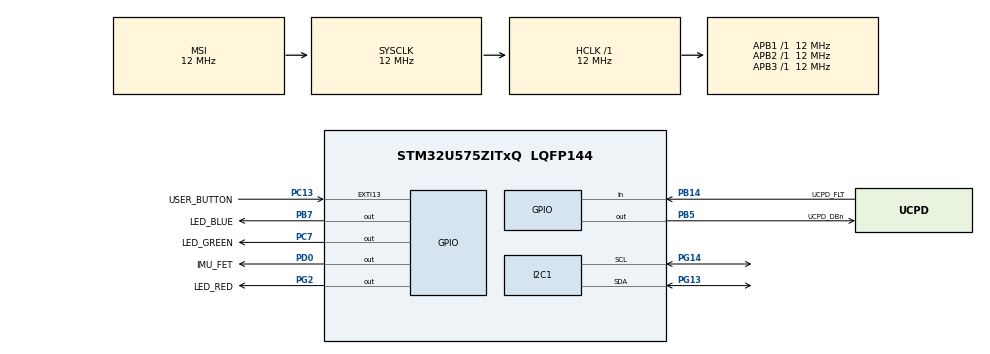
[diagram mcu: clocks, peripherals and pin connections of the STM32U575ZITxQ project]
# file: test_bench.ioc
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CORTEX_M33_NS.userName=CORTEX_M33
I2C1.Timing=0x40000A0B
Mcu.Family=STM32U5
Mcu.Name=STM32U575ZITxQ
Mcu.Package=LQFP144
NVIC.I2C1_ER_IRQn=true\:0\:0\:false\:false\:true\:true\:true\:true
NVIC.I2C1_EV_IRQn=true\:0\:0\:false\:false\:true\:true\:true\:true
NVIC.PriorityGroup=NVIC_PRIORITYGROUP_3
PA10.GPIO_Label=USART1_RX
PA10.GPIO_PuPd=GPIO_PULLDOWN
PA10.GPIO_Speed=GPIO_SPEED_FREQ_VERY_HIGH
PA10.Signal=USART1_RX
PA11.GPIO_Label=USB_OTG_FS_DM
PA11.GPIO_Speed=GPIO_SPEED_FREQ_VERY_HIGH
PA11.Signal=USB_OTG_FS_DM
PA12.GPIO_Label=USB_OTG_FS_DP
PA12.GPIO_Speed=GPIO_SPEED_FREQ_VERY_HIGH
PA12.Signal=USB_OTG_FS_DP
PA13\ (JTMS/SWDIO).Mode=Trace_Asynchronous_SW
PA13\ (JTMS/SWDIO).Signal=DEBUG_JTMS-SWDIO
PA14\ (JTCK/SWCLK).Mode=Trace_Asynchronous_SW
PA14\ (JTCK/SWCLK).Signal=DEBUG_JTCK-SWCLK
PA15\ (JTDI).GPIO_Label=UCPD1_CC1
PA15\ (JTDI).Signal=UCPD1_CC1
PA9.GPIO_Label=USART1_TX
PA9.GPIO_PuPd=GPIO_PULLDOWN
PA9.GPIO_Speed=GPIO_SPEED_FREQ_VERY_HIGH
PA9.Signal=USART1_TX
PB14.GPIO_Label=UCPD_FLT
PB14.Signal=GPIO_Input
PB15.GPIO_Label=UCPD1_CC2
PB15.Signal=UCPD1_CC2
PB3\ (JTDO/TRACESWO).Mode=Trace_Asynchronous_SW
PB3\ (JTDO/TRACESWO).Signal=DEBUG_JTDO-SWO
PB5.GPIO_Label=UCPD_DBn
PB5.Signal=GPIO_Output
PB7.GPIO_Label=LED_BLUE
PB7.GPIO_ModeDefaultOutputPP=GPIO_MODE_OUTPUT_PP
PB7.GPIO_PuPd=GPIO_PULLUP
PB7.GPIO_Speed=GPIO_SPEED_FREQ_HIGH
PB7.Signal=GPIO_Output
PC13.GPIO_Label=USER_BUTTON
PC13.GPIO_ModeDefaultEXTI=GPIO_MODE_IT_FALLING
PC13.Signal=GPXTI13
PC14-OSC32_IN\ (PC14).Mode=LSE-External-Oscillator
PC14-OSC32_IN\ (PC14).Signal=RCC_OSC32_IN
PC15-OSC32_OUT\ (PC15).Mode=LSE-External-Oscillator
PC15-OSC32_OUT\ (PC15).Signal=RCC_OSC32_OUT
PC2.GPIO_Label=VBUS_SENSE
PC2.Signal=ADC1_IN3
PC7.GPIO_Label=LED_GREEN
PC7.GPIO_PuPd=GPIO_PULLUP
PC7.GPIO_Speed=GPIO_SPEED_FREQ_HIGH
PC7.Signal=GPIO_Output
PD0.GPIO_Label=IMU_FET
PD0.PinState=GPIO_PIN_SET
PD0.Signal=GPIO_Output
PG13.GPIO_Pu=GPIO_PULLUP
PG13.GPIO_Speed=GPIO_SPEED_FREQ_VERY_HIGH
PG13.Mode=I2C
PG13.Signal=I2C1_SDA
PG14.GPIO_Pu=GPIO_PULLUP
PG14.GPIO_Speed=GPIO_SPEED_FREQ_VERY_HIGH
PG14.Mode=I2C
PG14.Signal=I2C1_SCL
PG2.GPIO_Label=LED_RED
PG2.GPIO_ModeDefaultOutputPP=GPIO_MODE_OUTPUT_PP
PG2.GPIO_PuPd=GPIO_PULLUP
PG2.GPIO_Speed=GPIO_SPEED_FREQ_HIGH
PG2.Signal=GPIO_Output
PWR.PowerMode=PWR_SMPS_SUPPLY
ProjectManager.HeapSize=0x200
ProjectManager.StackSize=0x400
ProjectManager.TargetToolchain=STM32CubeIDE
RCC.ADCCLockSelection=RCC_ADCDACCLKSOURCE_SYSCLK
RCC.ADCFreq_Value=12000000
RCC.AHBFreq_Value=12000000
RCC.APB1Freq_Value=12000000
RCC.APB1TimFreq_Value=12000000
RCC.APB2Freq_Value=12000000
RCC.APB2TimFreq_Value=12000000
RCC.APB3Freq_Value=12000000
RCC.CortexFreq_Value=12000000
RCC.DACCLockSelectionVirtual=RCC_DAC1CLKSOURCE_LSI
RCC.EPOD_VALUE=12000000
RCC.HCLKFreq_Value=12000000
RCC.HSE_VALUE=16000000
RCC.HSI48_VALUE=48000000
RCC.HSI_VALUE=16000000
RCC.I2C2CLockSelection=RCC_I2C2CLKSOURCE_SYSCLK
RCC.LSIDIV_VALUE=32000
RCC.MSIClockRange=RCC_MSIRANGE_3
RCC.MSI_VALUE=12000000
RCC.PLLN=80
RCC.SYSCLKFreq_VALUE=12000000
RCC.USBFreq_Value=48000000
RCC.VCOOutputFreq_Value=960000000
VP_ICACHE_VS_ICACHE.Mode=DirectMappedCache
VP_LPBAMQUEUE_VS_QUEUE.Mode=QUEUEMODE
VP_LPBAM_VS_SIG1.Mode=SmartRun
VP_LPBAM_VS_SIG4.Mode=LPDMA1
VP_MEMORYMAP_VS_MEMORYMAP.Mode=CurAppReg
VP_PWR_VS_DBSignals.Mode=DisableDeadBatterySignals
VP_PWR_VS_LPOM.Mode=PowerOptimisation
VP_PWR_VS_SECSignals.Mode=Security/Privilege
board=NUCLEO-U575ZI-Q

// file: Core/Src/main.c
/* USER CODE BEGIN Header */
/**
  ******************************************************************************
  * @file           : main.c
  * @brief          : Main program body
  ******************************************************************************
  * @attention
  *
  * Copyright (c) 2022 STMicroelectronics.
  * All rights reserved.
  *
  * This software is licensed under terms that can be found in the LICENSE file
  * in the root directory of this software component.
  * If no LICENSE file comes with this software, it is provided AS-IS.
  *
  ******************************************************************************
  */
/* USER CODE END Header */
#include "main.h"

/* USER CODE BEGIN Includes */
#include <string.h>
#include "stdbool.h"
#include "temp_sensor.h"

/* USER CODE END Includes */

I2C_HandleTypeDef hi2c1;

void SystemClock_Config(void);
static void SystemPower_Config(void);
static void MX_GPIO_Init(void);
static void MX_ICACHE_Init(void);
static void MX_I2C1_Init(void);

/* USER CODE BEGIN 0 */
Temperature temp;
/* USER CODE END 0 */

int main(void)
{

  /* MCU Configuration--------------------------------------------------------*/

  /* Reset of all peripherals, Initializes the Flash interface and the Systick. */
  HAL_Init();

  /* Configure the system clock */
  SystemClock_Config();

  /* Configure the System Power */
  SystemPower_Config();

  /* Initialize all configured peripherals */
  MX_GPIO_Init();
  MX_ICACHE_Init();
  MX_I2C1_Init();

  /* Infinite loop */
  /* USER CODE BEGIN WHILE */

  while (1)
  {
	  float room_temp = 0.0;
	  uint8_t command = 0x11;
	  temperature_init(&temp, &hi2c1, true);
	  temp.self_test();

	  temp.get_reading(&room_temp);

//	  for (uint16_t i = 0; i < 128; i++) {
//		  HAL_I2C_Master_Transmit(&hi2c2, i << 1, &command, sizeof(command), 10);
//		  HAL_Delay(10);
//	  }
    /* USER CODE END WHILE */

  }
}

void SystemClock_Config(void)
{
  RCC_OscInitTypeDef RCC_OscInitStruct = {0};
  RCC_ClkInitTypeDef RCC_ClkInitStruct = {0};

  /** Configure the main internal regulator output voltage
  */
  if (HAL_PWREx_ControlVoltageScaling(PWR_REGULATOR_VOLTAGE_SCALE4) != HAL_OK)
  {
    Error_Handler();
  }

  /** Initializes the CPU, AHB and APB buses clocks
  */
  RCC_OscInitStruct.OscillatorType = RCC_OSCILLATORTYPE_MSI;
  RCC_OscInitStruct.MSIState = RCC_MSI_ON;
  RCC_OscInitStruct.MSICalibrationValue = RCC_MSICALIBRATION_DEFAULT;
  RCC_OscInitStruct.MSIClockRange = RCC_MSIRANGE_3;
  RCC_OscInitStruct.PLL.PLLState = RCC_PLL_NONE;
  if (HAL_RCC_OscConfig(&RCC_OscInitStruct) != HAL_OK)
  {
    Error_Handler();
  }

  /** Initializes the CPU, AHB and APB buses clocks
  */
  RCC_ClkInitStruct.ClockType = RCC_CLOCKTYPE_HCLK|RCC_CLOCKTYPE_SYSCLK
                              |RCC_CLOCKTYPE_PCLK1|RCC_CLOCKTYPE_PCLK2
                              |RCC_CLOCKTYPE_PCLK3;
  RCC_ClkInitStruct.SYSCLKSource = RCC_SYSCLKSOURCE_MSI;
  RCC_ClkInitStruct.AHBCLKDivider = RCC_SYSCLK_DIV1;
  RCC_ClkInitStruct.APB1CLKDivider = RCC_HCLK_DIV1;
  RCC_ClkInitStruct.APB2CLKDivider = RCC_HCLK_DIV1;
  RCC_ClkInitStruct.APB3CLKDivider = RCC_HCLK_DIV1;

  if (HAL_RCC_ClockConfig(&RCC_ClkInitStruct, FLASH_LATENCY_0) != HAL_OK)
  {
    Error_Handler();
  }
}

/**
  * @brief Power Configuration
  * @retval None
  */
static void SystemPower_Config(void)
{
  HAL_PWREx_EnableVddIO2();

  /*
   * Disable the internal Pull-Up in Dead Battery pins of UCPD peripheral
   */
  HAL_PWREx_DisableUCPDDeadBattery();

  /*
   * Switch to SMPS regulator instead of LDO
   */
  if (HAL_PWREx_ConfigSupply(PWR_SMPS_SUPPLY) != HAL_OK)
  {
    Error_Handler();
  }
}

static void MX_I2C1_Init(void)
{

  hi2c1.Instance = I2C1;
  hi2c1.Init.Timing = 0x40000A0B;
  hi2c1.Init.OwnAddress1 = 0;
  hi2c1.Init.AddressingMode = I2C_ADDRESSINGMODE_7BIT;
  hi2c1.Init.DualAddressMode = I2C_DUALADDRESS_DISABLE;
  hi2c1.Init.OwnAddress2 = 0;
  hi2c1.Init.OwnAddress2Masks = I2C_OA2_NOMASK;
  hi2c1.Init.GeneralCallMode = I2C_GENERALCALL_DISABLE;
  hi2c1.Init.NoStretchMode = I2C_NOSTRETCH_DISABLE;
  if (HAL_I2C_Init(&hi2c1) != HAL_OK)
  {
    Error_Handler();
  }

  /** Configure Analogue filter
  */
  if (HAL_I2CEx_ConfigAnalogFilter(&hi2c1, I2C_ANALOGFILTER_ENABLE) != HAL_OK)
  {
    Error_Handler();
  }

  /** Configure Digital filter
  */
  if (HAL_I2CEx_ConfigDigitalFilter(&hi2c1, 0) != HAL_OK)
  {
    Error_Handler();
  }

}

static void MX_ICACHE_Init(void)
{

  /** Enable instruction cache in 1-way (direct mapped cache)
  */
  if (HAL_ICACHE_ConfigAssociativityMode(ICACHE_1WAY) != HAL_OK)
  {
    Error_Handler();
  }
  if (HAL_ICACHE_Enable() != HAL_OK)
  {
    Error_Handler();
  }

}

static void MX_GPIO_Init(void)
{
  GPIO_InitTypeDef GPIO_InitStruct = {0};

  /* GPIO Ports Clock Enable */
  __HAL_RCC_GPIOC_CLK_ENABLE();
  __HAL_RCC_GPIOB_CLK_ENABLE();
  __HAL_RCC_GPIOG_CLK_ENABLE();
  __HAL_RCC_GPIOA_CLK_ENABLE();
  __HAL_RCC_GPIOD_CLK_ENABLE();

  /*Configure GPIO pin Output Level */
  HAL_GPIO_WritePin(LED_RED_GPIO_Port, LED_RED_Pin, GPIO_PIN_RESET);

  /*Configure GPIO pin Output Level */
  HAL_GPIO_WritePin(LED_GREEN_GPIO_Port, LED_GREEN_Pin, GPIO_PIN_RESET);

  /*Configure GPIO pin Output Level */
  HAL_GPIO_WritePin(IMU_FET_GPIO_Port, IMU_FET_Pin, GPIO_PIN_SET);

  /*Configure GPIO pin Output Level */
  HAL_GPIO_WritePin(GPIOB, UCPD_DBn_Pin|LED_BLUE_Pin, GPIO_PIN_RESET);

  /*Configure GPIO pin : USER_BUTTON_Pin */
  GPIO_InitStruct.Pin = USER_BUTTON_Pin;
  GPIO_InitStruct.Mode = GPIO_MODE_IT_FALLING;
  GPIO_InitStruct.Pull = GPIO_NOPULL;
  HAL_GPIO_Init(USER_BUTTON_GPIO_Port, &GPIO_InitStruct);

  /*Configure GPIO pin : VBUS_SENSE_Pin */
  GPIO_InitStruct.Pin = VBUS_SENSE_Pin;
  GPIO_InitStruct.Mode = GPIO_MODE_ANALOG;
  GPIO_InitStruct.Pull = GPIO_NOPULL;
  HAL_GPIO_Init(VBUS_SENSE_GPIO_Port, &GPIO_InitStruct);

  /*Configure GPIO pin : UCPD_FLT_Pin */
  GPIO_InitStruct.Pin = UCPD_FLT_Pin;
  GPIO_InitStruct.Mode = GPIO_MODE_INPUT;
  GPIO_InitStruct.Pull = GPIO_NOPULL;
  HAL_GPIO_Init(UCPD_FLT_GPIO_Port, &GPIO_InitStruct);

  /*Configure GPIO pin : UCPD1_CC2_Pin */
  GPIO_InitStruct.Pin = UCPD1_CC2_Pin;
  GPIO_InitStruct.Mode = GPIO_MODE_ANALOG;
  GPIO_InitStruct.Pull = GPIO_NOPULL;
  HAL_GPIO_Init(UCPD1_CC2_GPIO_Port, &GPIO_InitStruct);

  /*Configure GPIO pin : LED_RED_Pin */
  GPIO_InitStruct.Pin = LED_RED_Pin;
  GPIO_InitStruct.Mode = GPIO_MODE_OUTPUT_PP;
  GPIO_InitStruct.Pull = GPIO_PULLUP;
  GPIO_InitStruct.Speed = GPIO_SPEED_FREQ_HIGH;
  HAL_GPIO_Init(LED_RED_GPIO_Port, &GPIO_InitStruct);

  /*Configure GPIO pin : LED_GREEN_Pin */
  GPIO_InitStruct.Pin = LED_GREEN_Pin;
  GPIO_InitStruct.Mode = GPIO_MODE_OUTPUT_PP;
  GPIO_InitStruct.Pull = GPIO_PULLUP;
  GPIO_InitStruct.Speed = GPIO_SPEED_FREQ_HIGH;
  HAL_GPIO_Init(LED_GREEN_GPIO_Port, &GPIO_InitStruct);

  /*Configure GPIO pins : USART1_TX_Pin USART1_RX_Pin */
  GPIO_InitStruct.Pin = USART1_TX_Pin|USART1_RX_Pin;
  GPIO_InitStruct.Mode = GPIO_MODE_AF_PP;
  GPIO_InitStruct.Pull = GPIO_PULLDOWN;
  GPIO_InitStruct.Speed = GPIO_SPEED_FREQ_VERY_HIGH;
  GPIO_InitStruct.Alternate = GPIO_AF7_USART1;
  HAL_GPIO_Init(GPIOA, &GPIO_InitStruct);

  /*Configure GPIO pins : USB_OTG_FS_DM_Pin USB_OTG_FS_DP_Pin */
  GPIO_InitStruct.Pin = USB_OTG_FS_DM_Pin|USB_OTG_FS_DP_Pin;
  GPIO_InitStruct.Mode = GPIO_MODE_AF_PP;
  GPIO_InitStruct.Pull = GPIO_NOPULL;
  GPIO_InitStruct.Speed = GPIO_SPEED_FREQ_VERY_HIGH;
  GPIO_InitStruct.Alternate = GPIO_AF10_USB;
  HAL_GPIO_Init(GPIOA, &GPIO_InitStruct);

  /*Configure GPIO pin : UCPD1_CC1_Pin */
  GPIO_InitStruct.Pin = UCPD1_CC1_Pin;
  GPIO_InitStruct.Mode = GPIO_MODE_ANALOG;
  GPIO_InitStruct.Pull = GPIO_NOPULL;
  HAL_GPIO_Init(UCPD1_CC1_GPIO_Port, &GPIO_InitStruct);

  /*Configure GPIO pin : IMU_FET_Pin */
  GPIO_InitStruct.Pin = IMU_FET_Pin;
  GPIO_InitStruct.Mode = GPIO_MODE_OUTPUT_PP;
  GPIO_InitStruct.Pull = GPIO_NOPULL;
  GPIO_InitStruct.Speed = GPIO_SPEED_FREQ_LOW;
  HAL_GPIO_Init(IMU_FET_GPIO_Port, &GPIO_InitStruct);

  /*Configure GPIO pin : UCPD_DBn_Pin */
  GPIO_InitStruct.Pin = UCPD_DBn_Pin;
  GPIO_InitStruct.Mode = GPIO_MODE_OUTPUT_PP;
  GPIO_InitStruct.Pull = GPIO_NOPULL;
  GPIO_InitStruct.Speed = GPIO_SPEED_FREQ_LOW;
  HAL_GPIO_Init(UCPD_DBn_GPIO_Port, &GPIO_InitStruct);

  /*Configure GPIO pin : LED_BLUE_Pin */
  GPIO_InitStruct.Pin = LED_BLUE_Pin;
  GPIO_InitStruct.Mode = GPIO_MODE_OUTPUT_PP;
  GPIO_InitStruct.Pull = GPIO_PULLUP;
  GPIO_InitStruct.Speed = GPIO_SPEED_FREQ_HIGH;
  HAL_GPIO_Init(LED_BLUE_GPIO_Port, &GPIO_InitStruct);

}

/* USER CODE BEGIN 4 */
void HAL_I2C_ErrorCallback(I2C_HandleTypeDef *hi2c)
{
	HAL_Delay(1);
}
/* USER CODE END 4 */

void Error_Handler(void)
{
  __disable_irq();
  while (1)
  {
  }
}
